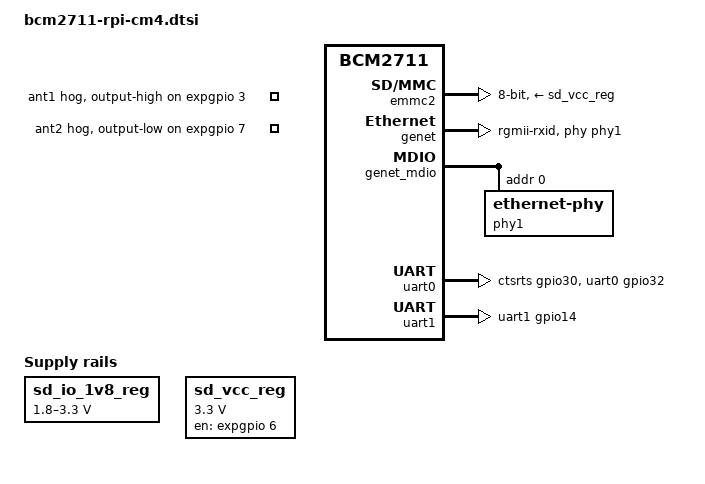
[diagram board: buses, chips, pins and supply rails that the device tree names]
/dts-v1/;
#include "bcm2711.dtsi"
#include "bcm2711-rpi.dtsi"
#include "bcm283x-rpi-wifi-bt.dtsi"
/ {
	compatible = "raspberrypi,4-compute-module", "brcm,bcm2711";
	chosen {
		stdout-path = "serial1:115200n8";
	};
	sd_io_1v8_reg: regulator-sd-io-1v8 {
		compatible = "regulator-gpio";
		regulator-name = "vdd-sd-io";
		regulator-min-microvolt = <1800000>;
		regulator-max-microvolt = <3300000>;
		regulator-boot-on;
		regulator-always-on;
		regulator-settling-time-us = <5000>;
		gpios = <&expgpio 4 GPIO_ACTIVE_HIGH>;
		states = <1800000 0x1>,
			 <3300000 0x0>;
		status = "okay";
	};
	sd_vcc_reg: regulator-sd-vcc {
		compatible = "regulator-fixed";
		regulator-name = "vcc-sd";
		regulator-min-microvolt = <3300000>;
		regulator-max-microvolt = <3300000>;
		regulator-boot-on;
		enable-active-high;
		gpio = <&expgpio 6 GPIO_ACTIVE_HIGH>;
	};
};
&bt {
	shutdown-gpios = <&expgpio 0 GPIO_ACTIVE_HIGH>;
};
&emmc2 {
	bus-width = <8>;
	vqmmc-supply = <&sd_io_1v8_reg>;
	vmmc-supply = <&sd_vcc_reg>;
	broken-cd;
	mmc-hs200-1_8v;
	status = "okay";
};
&expgpio {
	gpio-line-names = "BT_ON",
			  "WL_ON",
			  "PWR_LED_OFF",
			  "ANT1",
			  "VDD_SD_IO_SEL",
			  "CAM_GPIO",
			  "SD_PWR_ON",
			  "ANT2";
	ant1: ant1-hog {
		gpio-hog;
		gpios = <3 GPIO_ACTIVE_HIGH>;
		output-high;
		line-name = "ant1";
	};
	ant2: ant2-hog {
		gpio-hog;
		gpios = <7 GPIO_ACTIVE_HIGH>;
		output-low;
		line-name = "ant2";
	};
};
&genet {
	phy-handle = <&phy1>;
	phy-mode = "rgmii-rxid";
	status = "okay";
};
&genet_mdio {
	phy1: ethernet-phy@0 {
		reg = <0x0>;
	};
};
&uart0 {
	pinctrl-names = "default";
	pinctrl-0 = <&uart0_ctsrts_gpio30 &uart0_gpio32>;
	uart-has-rtscts;
};
&uart1 {
	pinctrl-names = "default";
	pinctrl-0 = <&uart1_gpio14>;
	status = "okay";
};
&wifi_pwrseq {
	reset-gpios = <&expgpio 1 GPIO_ACTIVE_LOW>;
};
